# wiz16b8m4ct3_0_WIZ16B8M4CT3 register map
Vendor: Texas Instruments
Registers are 32-bit, read-write, reset 0x0 unless marked. A register's access mark holds for its fields unless they carry their own. Offsets are as the file gives them; [hi:lo] are bit positions; {n}, {i} and the like mark numbered series.

## wiz16b8m4ct3_0_WIZ16B8M4CT3 (part 8 of 12)
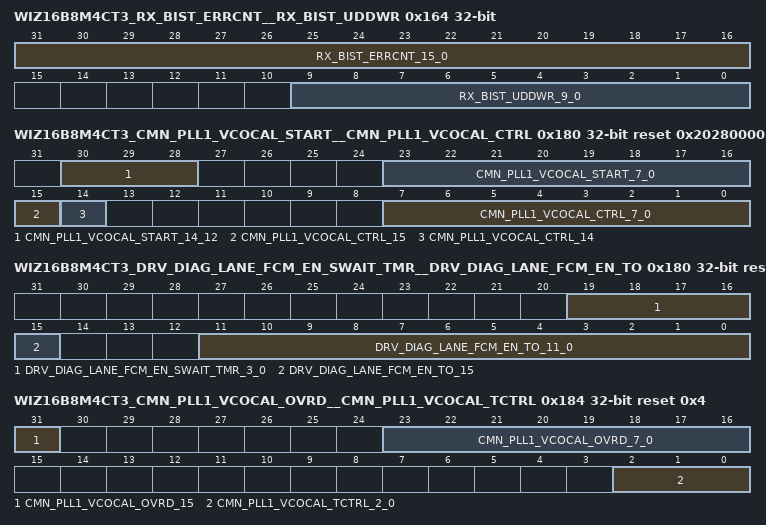
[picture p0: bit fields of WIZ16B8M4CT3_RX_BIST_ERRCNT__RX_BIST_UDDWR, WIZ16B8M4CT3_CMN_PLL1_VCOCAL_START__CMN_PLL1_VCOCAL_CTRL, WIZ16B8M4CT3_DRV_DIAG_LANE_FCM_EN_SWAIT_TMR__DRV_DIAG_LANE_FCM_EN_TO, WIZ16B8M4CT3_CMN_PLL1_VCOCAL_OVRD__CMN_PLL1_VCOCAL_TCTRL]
0x164 WIZ16B8M4CT3_RX_BIST_ERRCNT__RX_BIST_UDDWR access per field
  [31:16] RX_BIST_ERRCNT_15_0 ro — Receiver BIST error count: Indicates the number of BIST errors that have been observed by the receive BIST logic, since the last time the BIST error indicator logic was reset or restarted. This counter increments up to a maximum value of 16'hFFFF. Note : Due to the nature of the BIST PRBS error detection logic, when a bit error occurs in PRBS mode, two or three errors will be counted.
  [9:0] RX_BIST_UDDWR_9_0 wo — Receiver BIST user defined data: Writing a data word to this field will result in that data word being placed in the next available position in the receiver BIST user defined data FIFO. Note, when in 20 bit mode, all 10 of these bits are used. When in 16 bit mode, only the least significant 8 bits are used. Note: The FIFO in this implementation is 18 words deep. It is up to the user to not write more than 18 words of data into this FIFO. Exceeding this amount of data will generate unpredictable results.
0x180 WIZ16B8M4CT3_CMN_PLL1_VCOCAL_START__CMN_PLL1_VCOCAL_CTRL access per field reset 0x20280000
  [30:28] CMN_PLL1_VCOCAL_START_14_12 rw — VCO calibration initial step size control: This field specifies the initial step size for the VCO calibration state machine. The following are the values that can be used in this field, and the corresponding step sizes. 3'b000 : 1 3'b001 : 2 3'b010 : 4 3'b011 : 8 3'b100 : 16 3'b101 - 3'b111 : Reserved Note: This field is intended to be for diagnostics purposes only.
  [23:16] CMN_PLL1_VCOCAL_START_7_0 rw — VCO calibration code starting point value: This field specifies the starting VCO code that is used by the VCO calibration state machine. The purpose of this value is such that the VCO calibration process starts at a point that is, on average, relatively close to the final calibration point. This allows the calibration time to be reduced, on average. The encoding of this field is the same as what is described in the VCO calibration control register. Note: This field is intended to be for diagnostics purposes only. Note : This field must be set to a value that is always at least one step size away from the minimum and maximum calibration codes, and is a function of the step size specified in this register. For example, if the initial step size is 4, this value must be at least 4 greater than the minimum calibration code or 4 less than the maximum calibration code.
  [15] CMN_PLL1_VCOCAL_CTRL_15 rw — Start VCO calibration: Activating (1'b1) this bit will start a VCO calibration process. This bit must remain active until the VCO calibration process is complete (as indicated by the VCO calibration process done bit in this register). To start another VCO calibration process, the VCO calibration process done bit must have gone inactive from any prior calibration process. Note: This bit is intended to be for diagnostics purposes only. This calibration process is automatically activated internally by the PLL control state machine. When using this bit, the user must wait until after the internally activated process completes.
  [14] CMN_PLL1_VCOCAL_CTRL_14 ro — VCO calibration process done: This bit will be set to 1'b1 when the VCO calibration process is complete. It will be cleared by the deactivation of the Start VCO calibration bit in this register. Note: This bit is intended to be for diagnostics purposes only. Note: This bit is not likely to be observed as being set after internal automatic calibration is complete, because the internally generated run signal will be driven inactive immediately after the done signal is activated, and therefore the internal done signal will be cleared.
  [7:0] CMN_PLL1_VCOCAL_CTRL_7_0 ro — VCO calibration code: This is the calibration code that was determined by the VCO calibration process. This signal is valid when the VCO calibration process is complete. The values of this field correspond to different frequency bands the VCO will operate in. The frequency bands are controlled by the number of capacitors that are switched in the VCO analog circuit. This field specifies the number of capacitors that are switched in. The following are the values for this code: 8'b00000000: 0 Capacitors activated 8'b00000001: 1 Capacitor activated 8'b00000010: 2 Capacitors activated 8'b00000011: 3 Capacitors activated ... 8'b11111110: 254 Capacitors activated 8'b11111111: 255 Capacitors activated Note: This register is intended to be for diagnostics purposes only. Note: The reset value for this field is with the PLL controller power island switched off. In cases where this power island is switched on, the reset value be 8'h28.
0x180 WIZ16B8M4CT3_DRV_DIAG_LANE_FCM_EN_SWAIT_TMR__DRV_DIAG_LANE_FCM_EN_TO reset 0x601F4
  [19:16] DRV_DIAG_LANE_FCM_EN_SWAIT_TMR_3_0 — Lane fast common mode enable sample wait timer value: This specifies the number of reference clock cycles the fast establishment of common mode process will wait between changing the state of the signals controlling the analog common mode sense circuits, and testing the results of the new state.
  [15] DRV_DIAG_LANE_FCM_EN_TO_15 — Bypass fast establishment of common mode enable: When enabled, the fast establishment of common mode function will be bypassed. When bypassed, the lane fast common mode enable timeout value field in this register can be used to implement a programmable delay between when fast establishment of common mode is normally initiated, and when it will complete.
  [11:0] DRV_DIAG_LANE_FCM_EN_TO_11_0 — Lane fast common mode enable timeout value: The usage of the value of this field is a function of the state of the bypass fast establishment of common mode enable bit in this register. Bypass disabled (normal operation): This specifies the maximum number of reference clock cycles the fast establishment of common mode process will wait for the tx_{p,m} signals to be reported as above the reference voltage, before timing out. The default value of this register corresponds to a delay of 20 uSec. Bypass enabled: This can be used to specify the number of reference clock cycles between when fast establishment of common mode would normally be initiated, and when it is acknowledged to have been completed.
0x184 WIZ16B8M4CT3_CMN_PLL1_VCOCAL_OVRD__CMN_PLL1_VCOCAL_TCTRL reset 0x4
  [31] CMN_PLL1_VCOCAL_OVRD_15 — VCO calibration code override enable: Activating (1'b1) this bit allows the VCO code determined during the automatic VCO calibration process to be overridden by the value driven by the VCO calibration code override value field in this register. Note: This bit is intended to be for diagnostics purposes only. Note: This bit should not be activated while a calibration is currently in progress.
  [23:16] CMN_PLL1_VCOCAL_OVRD_7_0 — VCO calibration code override value: This field is used to override the VCO code determined during the automatic VCO calibration process. The VCO code driven on this field is valid when the VCO calibration code override enable bit in this register is active. The encoding of this field is the same as what is described in the VCO calibration control register. Note: This field is intended to be for diagnostics purposes only.
  [2:0] CMN_PLL1_VCOCAL_TCTRL_2_0 — VCO calibration initial time scale control: This field specifies the calibration start time scaling factor applied to the VCO calibration when running the initial step size for the calibration code if not set to 1. Setting this value to a value other than 1 will reduce the calibration measurement time by the amount specified below. Then when the final calibration steps are made the full calibration time will be used to get the appropriate amount of resolution. 3'b000 : Div 1 3'b001 : Div 2 3'b010 : Div 4 3'b011 : Div 8 3'b100 : Div 16 3'b101 : Div 32 3'b110 : Div 64 3'b111 : Div 128
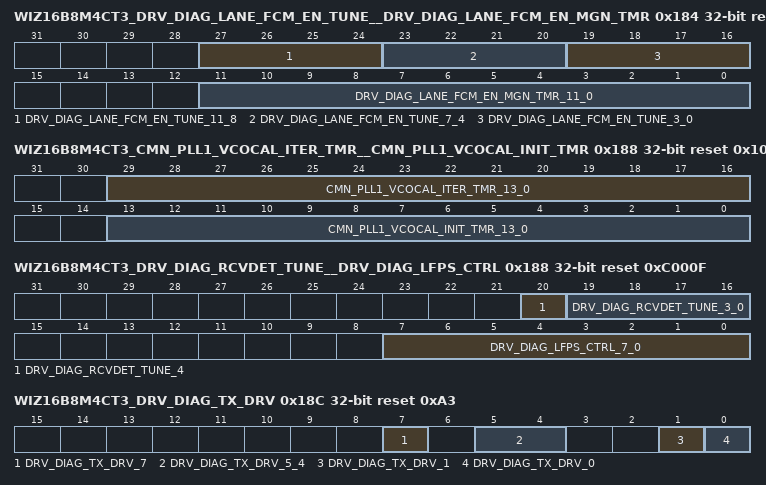
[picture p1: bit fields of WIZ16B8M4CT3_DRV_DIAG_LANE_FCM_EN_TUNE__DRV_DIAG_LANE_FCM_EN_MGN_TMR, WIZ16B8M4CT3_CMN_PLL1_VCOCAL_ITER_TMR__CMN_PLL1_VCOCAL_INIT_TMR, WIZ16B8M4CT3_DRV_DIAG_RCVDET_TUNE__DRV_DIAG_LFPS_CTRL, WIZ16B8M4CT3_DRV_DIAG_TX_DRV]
0x184 WIZ16B8M4CT3_DRV_DIAG_LANE_FCM_EN_TUNE__DRV_DIAG_LANE_FCM_EN_MGN_TMR reset 0x8C40096
  [27:24] DRV_DIAG_LANE_FCM_EN_TUNE_11_8 — Common mode sense reference DAC voltage initial test: This field sets the common mode detect reference voltage for the common mode detect comparator, when the fast establishment of common mode function is checking the initial state of the txda_cm_sense_comp_out signal. This field drives the txda_cm_sense_vref_dac signal going to the analog, and it is only driven when the fast establishment of common mode function is enabled. 4'b0000 : Minimum ... 4'b1111 : Maximum
  [23:20] DRV_DIAG_LANE_FCM_EN_TUNE_7_4 — Common mode sense reference DAC voltage high test: This field sets the common mode detect reference voltage for the common mode detect comparator, when the fast establishment of common mode function is waiting for the txda_cm_sense_comp_out signal from the analog to be driven high. This field drives the txda_cm_sense_vref_dac signal going to the analog, and it is only driven when the fast establishment of common mode function is enabled. 4'b0000 : Minimum ... 4'b1111 : Maximum
  [19:16] DRV_DIAG_LANE_FCM_EN_TUNE_3_0 — Common mode sense reference DAC voltage low test: This field sets the common mode detect reference voltage for the common mode detect comparator, when the fast establishment of common mode function is waiting for the txda_cm_sense_comp_out signal from the analog to be driven low. This field drives the txda_cm_sense_vref_dac signal going to the analog, and it is only driven when the fast establishment of common mode function is enabled. 4'b0000 : Minimum ... 4'b1111 : Maximum
  [11:0] DRV_DIAG_LANE_FCM_EN_MGN_TMR_11_0 — Lane fast common mode enable margin timer value: This specifies the number of reference clock cycles the fast establishment of common mode process will enable all the margin segments for. The default value of this register corresponds to a delay of 6 uSec.
0x188 WIZ16B8M4CT3_CMN_PLL1_VCOCAL_ITER_TMR__CMN_PLL1_VCOCAL_INIT_TMR reset 0x1003E8
  [29:16] CMN_PLL1_VCOCAL_ITER_TMR_13_0 — Iteration wait timer value: This is the number of clocks to wait between when a calibration code is driven to the analog, and when the clock rates are measured.
  [13:0] CMN_PLL1_VCOCAL_INIT_TMR_13_0 — Initialization wait timer value: This is the number of clocks to wait between when the analog VCO calibration circuits are enabled, and when the first calibration code is driven to the analog. Note: The reset value for this field corresponds to a time of 10 uSec.
0x188 WIZ16B8M4CT3_DRV_DIAG_RCVDET_TUNE__DRV_DIAG_LFPS_CTRL reset 0xC000F
  [20] DRV_DIAG_RCVDET_TUNE_4 — Receiver detect comparators output and or control: This bit controls how the receiver detect comparators are used to drive the txda_rcvdet_detected_n signal to the digital. This bit drives the txda_rcvdet_and_orb signal going to the analog. 1'b0: Comparator outputs are ORed to drive txda_rcvdet_detected_n. 1'b1: Comparator outputs are ANDed to drive txda_rcvdet_detected_n.
  [19:16] DRV_DIAG_RCVDET_TUNE_3_0 — Receiver detect reference DAC voltage: This field sets the receiver detect reference voltage for the receiver detect comparator. This field drives the txda_rcvdet_vref_dac signal going to the analog. 4'b0000 : Minimum ... 4'b1111 : Maximum
  [7:0] DRV_DIAG_LFPS_CTRL_7_0 — LFPS half period clocks: Specifies the number of clock cycles required to implement one half of a LFPS period, by the transmitter LFPS controller.
0x18C WIZ16B8M4CT3_CMN_PLL1_VCOCAL_REFTIM_START reset 0xC5F
  [13:0] CMN_PLL1_VCOCAL_REFTIM_START_13_0 — PLL VCO calibration reference clock timer start value : This is the value that is loaded into the reference clock timer as the starting point for that timer, when running VCO calibration. The value in this field must correspond to a time that is approximately one full spread spectrum cycle long (31.67 uSec) Note: The actual number of clocks counted is one larger than what is specified by this field.
0x18C WIZ16B8M4CT3_DRV_DIAG_TX_DRV reset 0xA3
  [7] DRV_DIAG_TX_DRV_7 — TX boost enable: Increases the transmitter amplitude for fast data transitions, by controlling the txda_drv_boost_en signal going to the analog.
  [5:4] DRV_DIAG_TX_DRV_5_4 — TX boost tune: Controls the transmitter boost amplitude when the transmitter boost function is enabled using the TX boost enable bit in this register, by controlling the txda_drv_boost_tune signal going to the analog. The following specifies the encoding of this field. 2'b00: Minimum Boost 2'b01: 2'b10: 2'b11: Maximum Boost
  [1] DRV_DIAG_TX_DRV_1 — TX pre-driver pull up control: When the pre-driver is disabled, this bit controls the state of the pre-driver output, by controlling the txda_drv_predrv_pullup signal going to the analog. 1'b0 : Pulled low 1'b1 : Pulled high
  [0] DRV_DIAG_TX_DRV_0 — TX driver margin type: Selects the margining type the driver will operate in, by controlling the txda_drv_margin_type signal going to the analog. 1'b0 : Classical margining - High power margining that complies with the driver differential and common-mode output impedance specs. 1'b1 : Low-Power margining - Low power margining that complies with the driver differential output impedance spec. However, this violates the driver common-mode output impedance spec to save power whenever a reduced swing driver configuration is used. Note: When fast establishment of common mode is active, the analog signal that this drives will be forced to 1'b0.
0x190 WIZ16B8M4CT3_CMN_PLL1_VCOCAL_PLLCNT_START reset 0xC5F
  [13:0] CMN_PLL1_VCOCAL_PLLCNT_START_13_0 — PLL VCO calibration PLL clock counter start value : This is the value that is loaded into the PLL clock counter as the starting point for that counter, when running VCO calibration. When programming this register, it is important to understand how the frequency of the cmnda_pll0_fb_divider_clk is calculated relative to the reference clock. This is described in section 10.4 Dual VCO PLL on page 411. Note: The actual number of clocks counted is one larger than what is specified by this field.
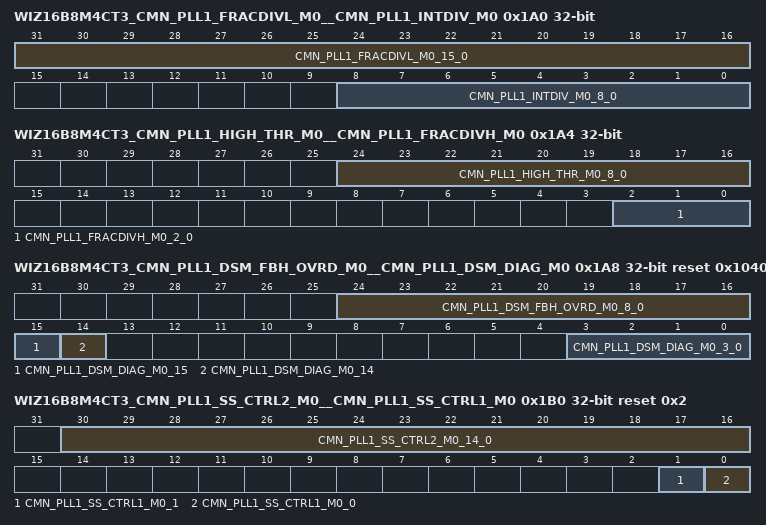
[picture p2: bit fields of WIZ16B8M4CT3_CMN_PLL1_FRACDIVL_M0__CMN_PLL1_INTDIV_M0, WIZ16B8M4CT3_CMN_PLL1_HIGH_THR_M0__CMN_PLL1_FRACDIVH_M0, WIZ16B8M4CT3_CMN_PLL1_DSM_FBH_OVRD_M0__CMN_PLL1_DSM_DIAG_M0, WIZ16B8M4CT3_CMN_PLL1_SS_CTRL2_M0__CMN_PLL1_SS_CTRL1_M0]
0x1A0 WIZ16B8M4CT3_CMN_PLL1_FRACDIVL_M0__CMN_PLL1_INTDIV_M0
  [31:16] CMN_PLL1_FRACDIVL_M0_15_0 — pll_fb_div_fractional: Value of the pll_fb_div_fractional[15:0] signal.
  [8:0] CMN_PLL1_INTDIV_M0_8_0 — pll_fb_div_integer value: Value of the pll_fb_div_integer signal.
0x1A4 WIZ16B8M4CT3_CMN_PLL1_HIGH_THR_M0__CMN_PLL1_FRACDIVH_M0
  [24:16] CMN_PLL1_HIGH_THR_M0_8_0 — pll_fb_div_high_theshold: Value of the pll_fb_div_high_threshold signal. The value of this register should be 2/3 the value of the combined integer and fractional divider values, and rounded up to the next even number.
  [2:0] CMN_PLL1_FRACDIVH_M0_2_0 — pll_fb_div_fractional: Value of the pll_fb_div_fractional[18:16] signal.
0x1A8 WIZ16B8M4CT3_CMN_PLL1_DSM_FBH_OVRD_M0__CMN_PLL1_DSM_DIAG_M0 reset 0x104004
  [24:16] CMN_PLL1_DSM_FBH_OVRD_M0_8_0 — PLL feedback divider high override value : When enabled by the PLL feedback divider override enable bit in the PLL 1 delta sigma modulator diagnostics register mode 0 on page 126, the value in this field will be used to override the value on the cmnda_pll1_fb_div_high signal. Note: The value of this register should be 2/3 the value of the combined PLL feedback divider high and low values, and rounded up to the next even number.
  [15] CMN_PLL1_DSM_DIAG_M0_15 — Delta sigma bypass enable: When set to 1'b1, the delta sigma modulator will be bypassed, and the output will be the value specified for the internal pll_fb_div_integer signal.
  [14] CMN_PLL1_DSM_DIAG_M0_14 — PLL feedback divider override enable : When active (1'b1), the feedback divider low and high override values in the PLL 1 delta sigma modulator feedback divider value high override register mode 0 on page 126 and PLL 1 delta sigma modulator feedback divider value low override register mode 0 on page 126 registers will be used to override the feedback divider values driven to the analog.
  [3:0] CMN_PLL1_DSM_DIAG_M0_3_0 — PLL feedback divider latency adjustment: This signal specifies a value to be subtracted from the feedback divider settings before they are output on the cmnda_pll1_fb_div_high and cmnda_pll1_fb_div_low signals.
0x1AC WIZ16B8M4CT3_CMN_PLL1_DSM_FBL_OVRD_M0 reset 0x10
  [8:0] CMN_PLL1_DSM_FBL_OVRD_M0_8_0 — PLL feedback divider low override value : When enabled by the PLL feedback divider override enable bit in the PLL 1 delta sigma modulator diagnostics register mode 0 on page 126, the value in this field will be used to override the value on the cmnda_pll1_fb_div_low signal.
0x1B0 WIZ16B8M4CT3_CMN_PLL1_SS_CTRL2_M0__CMN_PLL1_SS_CTRL1_M0 reset 0x2
  [30:16] CMN_PLL1_SS_CTRL2_M0_14_0 — Amplitude step size: Value of the amplitude_step_size pin on the spread spectrum waveform generator. Note: This field should not be set to 0 when spread spectrum is enabled.
  [1] CMN_PLL1_SS_CTRL1_M0_1 — Spread spectrum waveform generator disable: Setting this bit to a 1'b1 will disable the spread spectrum waveform generator.
  [0] CMN_PLL1_SS_CTRL1_M0_0 — Spread spectrum enable during VCO calibration : Setting this bit to a 1'b1 will enable the spread spectrum function while VCO calibration is taking place.
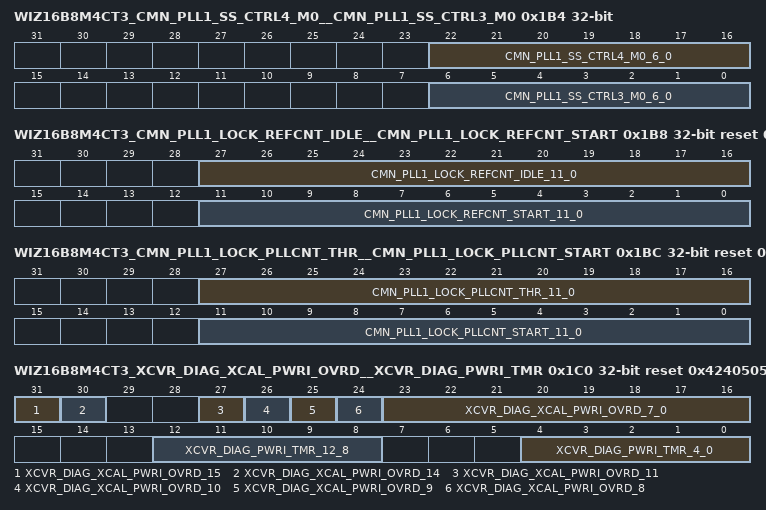
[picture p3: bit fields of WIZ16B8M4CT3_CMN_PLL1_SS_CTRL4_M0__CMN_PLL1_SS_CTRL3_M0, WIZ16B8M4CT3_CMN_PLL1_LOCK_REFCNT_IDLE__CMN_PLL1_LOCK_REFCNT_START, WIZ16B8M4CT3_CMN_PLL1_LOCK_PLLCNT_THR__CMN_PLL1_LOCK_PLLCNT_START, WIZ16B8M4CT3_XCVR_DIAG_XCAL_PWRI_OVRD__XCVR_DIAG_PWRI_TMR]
0x1B4 WIZ16B8M4CT3_CMN_PLL1_SS_CTRL4_M0__CMN_PLL1_SS_CTRL3_M0
  [22:16] CMN_PLL1_SS_CTRL4_M0_6_0 — Time step size: Value for the time_step_size pin on the spread spectrum waveform generator. Note: This field should not be set to 0 when spread spectrum is enabled.
  [6:0] CMN_PLL1_SS_CTRL3_M0_6_0 — Number of steps: Value of the num_steps pin on the spread spectrum waveform generator. Note: This field should not be set to 0 when spread spectrum is enabled.
0x1B8 WIZ16B8M4CT3_CMN_PLL1_LOCK_REFCNT_IDLE__CMN_PLL1_LOCK_REFCNT_START reset 0x400C8
  [27:16] CMN_PLL1_LOCK_REFCNT_IDLE_11_0 — PLL lock reference counter idle value : This is the value used by the PLL lock detection logic to specify the number of reference clocks between each phase of counting PLL clocks.
  [11:0] CMN_PLL1_LOCK_REFCNT_START_11_0 — PLL lock reference counter start value : This is the value that is loaded into the PLL lock detect reference counter as the starting point for that counter, when checking for PLL lock. Note: The value required here is a function of the PLL feedback divider clock mode and the reference clock frequency. Overview information in regards to this can be found in section 4.2 Reference Clock Related Clocking and Reset on page 288 and section 4.9 Reference Clock Related Clock Rate Summary on page 319. The following bullet points specify the required time the value in this register is required to generate. By default, the value in this register is set for FBR mode with a 100 MHz reference clock. FBR mode and reference clock frequency greater than or equal to 100 MHz: 2 uSec FBR mode and reference clock frequency less than 100 MHz: 8 uSec DR mode: 800 nSec
0x1BC WIZ16B8M4CT3_CMN_PLL1_LOCK_PLLCNT_THR__CMN_PLL1_LOCK_PLLCNT_START reset 0x300C8
  [27:16] CMN_PLL1_LOCK_PLLCNT_THR_11_0 — PLL lock counter threshold value : This is the value used by the PLL lock detection logic to determine if the PLL has locked. If the two counters in the PLL lock detection logic differ by less than this value, the PLL is considered locked.
  [11:0] CMN_PLL1_LOCK_PLLCNT_START_11_0 — PLL lock PLL counter start value : This is the value that is loaded into the PLL lock detect PLL counter as the starting point for that counter, when checking for PLL lock. The value is the number of PLL feedback divider clock edges that are expected during the time specified by the PLL 0 lock reference counter start value register on page 115. When programming this register, it is important to understand how the frequency of the cmnda_pll0_fb_divider_clk is calculated relative to the reference clock. This is described in section 10.4 Dual VCO PLL on page 411.
0x1C0 WIZ16B8M4CT3_XCVR_DIAG_XCAL_PWRI_OVRD__XCVR_DIAG_PWRI_TMR access per field reset 0x4240505
  [31] XCVR_DIAG_XCAL_PWRI_OVRD_15 rw — Power island controller input override enable: When enabled, the power island control state machine input override bits in this register will drive the power island control state machine directly, and override any control from other state machines in the macro. Note: The CDB power island must be triggered to be enabled, by accessing a register outside of the common control module control and diagnostic registers space, prior to enabling this function. Note: This bit must never change state in the same register write that any of the override bits it controls in this register are changed. Note: The value of this field must be the same for all lanes that make up a link. 1'b0: Override disabled 1'b1: Override enabled
  [30] XCVR_DIAG_XCAL_PWRI_OVRD_14 rw — Power island controller output override enable: When enabled, the power island control state machine output override bits in this register will drive the power island control state machine outputs, and override any control from power island control state machine. Note: This bit must never change state in the same register write that any of the override bits it controls in this register are changed. Note: The value of this field must be the same for all lanes that make up a link. 1'b0: Override disabled 1'b1: Override enabled
  [27] XCVR_DIAG_XCAL_PWRI_OVRD_11 rw — Power suspend request override: When enabled, this bit will override the power_suspend_req input of the power island control state machine. Note: The value of this field must be the same for all lanes that make up a link.
  [26] XCVR_DIAG_XCAL_PWRI_OVRD_10 ro — Power suspend acknowledge: This is the current state of the power_suspend_ack output from the power island control state machine. Note: This bit will always be set to 1'b1 after the power island is enabled, as a function of the power island controller input override enable bit in this register.
  [25] XCVR_DIAG_XCAL_PWRI_OVRD_9 rw — Power recover request override: When enabled, this bit will override the power_recover_req input of the power island control state machine. Note: The value of this field must be the same for all lanes that make up a link.
  [24] XCVR_DIAG_XCAL_PWRI_OVRD_8 ro — Power recover acknowledge: This is the current state of the power_recover_ack output from the power island control state machine. Note: This bit will always be set to 1'b1 after the power island is enabled, as a function of the power island controller input override enable bit in this register.
  [23:16] XCVR_DIAG_XCAL_PWRI_OVRD_7_0 rw — Power island controller output override: When enabled, the bits in this field will override the output signals from the power island control state machine. The following are the power island control state machine output signals, and the bits in this field that they are associated with. Bit 7: state_sandh Bit 6: state_ret_save Bit 5: state_ret_restore (active low) Bit 4: power_en_ph_1 Bit 3: power_en_ph_2 Bit 2: power_isolation Bit 1: power_por_reset_n Bit 0: power_rstr_reset_n The default value of the bits in this register are such that the power island is not forced to be switched on when the power island controller output override enable bit in this register is enabled. When using this register to switch this power island on and off, the bits in this field are required to change in a specific order with individual register writes. The writes must happen in the order specified below. 8'b00100100 : Power island is not being forced on 8'b10100100 8'b10110100 8'b10111100 8'b10111111 8'b10111011 8'b00111011 : Power island is being forced on 8'b10111011 8'b10111111 8'b11111111 8'b10111111 8'b10111110 8'b10100110 : Power island is being forced off, and in state retention 8'b10110110 8'b10111110 8'b10111111 8'b10011111 8'b10111111 8'b10111011 8'b00111011 : Power island is being forced on, with state restored Note: The value of this field must be the same for all lanes that make up a link.
  [12:8] XCVR_DIAG_PWRI_TMR_12_8 rw — Power enable phase 2 timer value: This specifies the number of PSM clock cycles the power island control state machines in the transceiver will wait in the power phase 2 enable states, in order to allow enough time for the second phase of the switched domain to power up, before deactivating the isolation functions. The default value of this register corresponds to a delay of 40 nSec. Note: A value of 0 in this field is not valid, and will result in a delay of 1 clock cycle. Note: The value of this field must be the same for all lanes that make up a link.
  [4:0] XCVR_DIAG_PWRI_TMR_4_0 rw — Power enable phase 1 timer value: This specifies the number of PSM clock cycles the power island control state machines in the transceiver will wait in the power phase 1 enable states, in order to allow enough time for the first phase of the switched domain to power up, before enabling the second phase of the power up. The default value of this register corresponds to a delay of 40 nSec. Note: A value of 0 in this field is not valid, and will result in a delay of 1 clock cycle. Note: The value of this field must be the same for all lanes that make up a link.
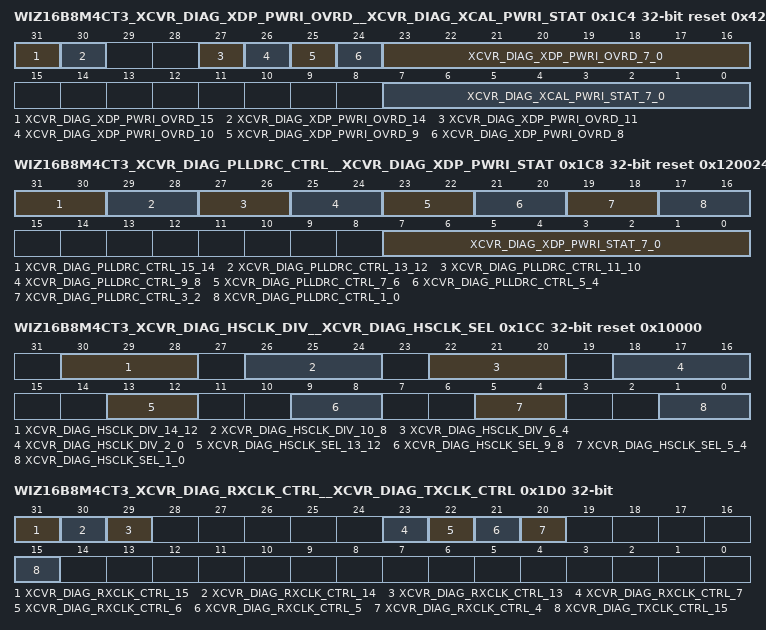
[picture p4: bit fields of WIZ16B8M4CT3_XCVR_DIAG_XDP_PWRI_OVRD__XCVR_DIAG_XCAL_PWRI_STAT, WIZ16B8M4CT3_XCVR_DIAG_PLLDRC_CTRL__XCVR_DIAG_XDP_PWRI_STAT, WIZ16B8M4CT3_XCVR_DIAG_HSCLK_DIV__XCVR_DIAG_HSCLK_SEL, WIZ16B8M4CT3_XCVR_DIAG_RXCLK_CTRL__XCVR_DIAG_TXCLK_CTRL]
0x1C4 WIZ16B8M4CT3_XCVR_DIAG_XDP_PWRI_OVRD__XCVR_DIAG_XCAL_PWRI_STAT access per field reset 0x4240024
  [31] XCVR_DIAG_XDP_PWRI_OVRD_15 rw — Power island controller input override enable: When enabled, the power island control state machine input override bits in this register will drive the power island control state machine directly, and override any control from other state machines in the macro. Note: The CDB power island must be triggered to be enabled, by accessing a register outside of the common control module control and diagnostic registers space, prior to enabling this function. Note: This bit must never change state in the same register write that any of the override bits it controls in this register are changed. Note: The value of this field must be the same for all lanes that make up a link. 1'b0: Override disabled 1'b1: Override enabled
  [30] XCVR_DIAG_XDP_PWRI_OVRD_14 rw — Power island controller output override enable: When enabled, the power island control state machine output override bits in this register will drive the power island control state machine outputs, and override any control from power island control state machine. Note: This bit must never change state in the same register write that any of the override bits it controls in this register are changed. Note: The value of this field must be the same for all lanes that make up a link. 1'b0: Override disabled 1'b1: Override enabled
  [27] XCVR_DIAG_XDP_PWRI_OVRD_11 rw — Power suspend request override: When enabled, this bit will override the power_suspend_req input of the power island control state machine. Note: The value of this field must be the same for all lanes that make up a link.
  [26] XCVR_DIAG_XDP_PWRI_OVRD_10 ro — Power suspend acknowledge: This is the current state of the power_suspend_ack output from the power island control state machine. Note: This bit will always be set to 1'b1 after the power island is enabled, as a function of the power island controller input override enable bit in this register.
  [25] XCVR_DIAG_XDP_PWRI_OVRD_9 rw — Power recover request override: When enabled, this bit will override the power_recover_req input of the power island control state machine. Note: The value of this field must be the same for all lanes that make up a link.
  [24] XCVR_DIAG_XDP_PWRI_OVRD_8 ro — Power recover acknowledge: This is the current state of the power_recover_ack output from the power island control state machine. Note: This bit will always be set to 1'b1 when the power island controller input override enable bit in this register.
  [23:16] XCVR_DIAG_XDP_PWRI_OVRD_7_0 rw — Power island controller output override: When enabled, the bits in this field will override the output signals from the power island control state machine. The following are the power island control state machine output signals, and the bits in this field that they are associated with. Bit 7: state_sandh Bit 6: state_ret_save Bit 5: state_ret_restore (active low) Bit 4: power_en_ph_1 Bit 3: power_en_ph_2 Bit 2: power_isolation Bit 1: power_por_reset_n Bit 0: power_rstr_reset_n The default value of the bits in this register are such that the power island is not forced to be switched on when the power island controller output override enable bit in this register is enabled. When using this register to switch this power island on and off, the bits in this field are required to change in a specific order with individual register writes. The writes must happen in the order specified below. 8'b00100100 : Power island is not being forced on 8'b10100100 8'b10110100 8'b10111100 8'b10111111 8'b10111011 8'b00111011 : Power island is being forced on 8'b10111011 8'b10111111 8'b11111111 8'b10111111 8'b10111110 8'b10100110 : Power island is being forced off, and in state retention 8'b10110110 8'b10111110 8'b10111111 8'b10011111 8'b10111111 8'b10111011 8'b00111011 : Power island is being forced on, with state restored Note: The value of this field must be the same for all lanes that make up a link.
  [7:0] XCVR_DIAG_XCAL_PWRI_STAT_7_0 ro — Power island controller output status: This field indicates the current state of the output signals from the power island control state machine. The following are the power island control state machine output signals, and the bits in this field that they are associated with. Bit 7: state_sandh Bit 6: state_ret_save Bit 5: state_ret_restore (active low) Bit 4: power_en_ph_1 Bit 3: power_en_ph_2 Bit 2: power_isolation Bit 1: power_por_reset_n Bit 0: power_rstr_reset_n
0x1C8 WIZ16B8M4CT3_XCVR_DIAG_PLLDRC_CTRL__XCVR_DIAG_XDP_PWRI_STAT access per field reset 0x120024
  [31:30] XCVR_DIAG_PLLDRC_CTRL_15_14 rw — Digital PLL clock select standard mode 3: This bit controls which full rate PLL clock is selected, when xcvr_standard_mode is set to 2'b11. 2'b00 : PLL clock 0 from the PLL 0. 2'b01 : PLL clock 1 from the PLL 0. 2'b10 : PLL clock 0 from the PLL 1. 2'b11 : PLL clock 1 from the PLL 1.
  [29:28] XCVR_DIAG_PLLDRC_CTRL_13_12 rw — Digital PLL data rate divider standard mode 3 value: This field will directly control the xcvr_pll_clk_datart_div signal, which controls which divided clock is selected when generating the xcvr_pll_clk_datart clock, when xcvr_standard_mode is set to 2'b11. 2'b00 : Divide by 1. 2'b01 : Divide by 2. 2'b10 : Divide by 4. 2'b11 : Divide by 8.
  [27:26] XCVR_DIAG_PLLDRC_CTRL_11_10 rw — Digital PLL clock select standard mode 2: This bit controls which full rate PLL clock is selected, when xcvr_standard_mode is set to 2'b10. 2'b00 : PLL clock 0 from the PLL 0. 2'b01 : PLL clock 1 from the PLL 0. 2'b10 : PLL clock 0 from the PLL 1. 2'b11 : PLL clock 1 from the PLL 1.
  [25:24] XCVR_DIAG_PLLDRC_CTRL_9_8 rw — Digital PLL data rate divider standard mode 2 value: This field will directly control the xcvr_pll_clk_datart_div signal, which controls which divided clock is selected when generating the xcvr_pll_clk_datart clock, when xcvr_standard_mode is set to 2'b10. 2'b00 : Divide by 1. 2'b01 : Divide by 2. 2'b10 : Divide by 4. 2'b11 : Divide by 8.
  [23:22] XCVR_DIAG_PLLDRC_CTRL_7_6 rw — Digital PLL clock select standard mode 1: This bit controls which full rate PLL clock is selected, when xcvr_standard_mode is set to 2'b01. 2'b00 : PLL clock 0 from the PLL 0. 2'b01 : PLL clock 1 from the PLL 0. 2'b10 : PLL clock 0 from the PLL 1. 2'b11 : PLL clock 1 from the PLL 1.
  [21:20] XCVR_DIAG_PLLDRC_CTRL_5_4 rw — Digital PLL data rate divider standard mode 1 value: This field will directly control the xcvr_pll_clk_datart_div signal, which controls which divided clock is selected when generating the xcvr_pll_clk_datart clock, when xcvr_standard_mode is set to 2'b01. 2'b00 : Divide by 1. 2'b01 : Divide by 2. 2'b10 : Divide by 4. 2'b11 : Divide by 8.
  [19:18] XCVR_DIAG_PLLDRC_CTRL_3_2 rw — Digital PLL clock select standard mode 0: This bit controls which full rate PLL clock is selected, when xcvr_standard_mode is set to 2'b00. 2'b00 : PLL clock 0 from the PLL 0. 2'b01 : PLL clock 1 from the PLL 0. 2'b10 : PLL clock 0 from the PLL 1. 2'b11 : PLL clock 1 from the PLL 1.
  [17:16] XCVR_DIAG_PLLDRC_CTRL_1_0 rw — Digital PLL data rate divider standard mode 0 value: This field will directly control the xcvr_pll_clk_datart_div signal, which controls which divided clock is selected when generating the xcvr_pll_clk_datart clock, when xcvr_standard_mode is set to 2'b00. 2'b00 : Divide by 1. 2'b01 : Divide by 2. 2'b10 : Divide by 4. 2'b11 : Divide by 8.
  [7:0] XCVR_DIAG_XDP_PWRI_STAT_7_0 ro — Power island controller output status: This field indicates the current state of the output signals from the power island control state machine. The following are the power island control state machine output signals, and the bits in this field that they are associated with. Bit 7: state_sandh Bit 6: state_ret_save Bit 5: state_ret_restore (active low) Bit 4: power_en_ph_1 Bit 3: power_en_ph_2 Bit 2: power_isolation Bit 1: power_por_reset_n Bit 0: power_rstr_reset_n
0x1CC WIZ16B8M4CT3_XCVR_DIAG_HSCLK_DIV__XCVR_DIAG_HSCLK_SEL reset 0x10000
  [30:28] XCVR_DIAG_HSCLK_DIV_14_12 — Transceiver clock divider select standard mode 3: This field selects the divider value used to divide the selected analog high speed clock by when generating the transmit and receive clocks, when xcvr_standard_mode is set to 2'b11, by driving the xcvrda_xcvr_clk_div_sel signal to the analog, as specified below. 3'b000: Div 1 3'b001: Div 2 3'b010: Div 3 3'b011: Div 4 3'b100: Div 5 3'b101: Div 6 3'b110: Div 7 3'b111: Div 8
  [26:24] XCVR_DIAG_HSCLK_DIV_10_8 — Transceiver clock divider select standard mode 2: This field selects the divider value used to divide the selected analog high speed clock by when generating the transmit and receive clocks, when xcvr_standard_mode is set to 2'b10, by driving the xcvrda_xcvr_clk_div_sel signal to the analog, as specified below. 3'b000: Div 1 3'b001: Div 2 3'b010: Div 3 3'b011: Div 4 3'b100: Div 5 3'b101: Div 6 3'b110: Div 7 3'b111: Div 8
  [22:20] XCVR_DIAG_HSCLK_DIV_6_4 — Transceiver clock divider select standard mode 1: This field selects the divider value used to divide the selected analog high speed clock by when generating the transmit and receive clocks, when xcvr_standard_mode is set to 2'b01, by driving the xcvrda_xcvr_clk_div_sel signal to the analog, as specified below. 3'b000: Div 1 3'b001: Div 2 3'b010: Div 3 3'b011: Div 4 3'b100: Div 5 3'b101: Div 6 3'b110: Div 7 3'b111: Div 8
  [18:16] XCVR_DIAG_HSCLK_DIV_2_0 — Transceiver clock divider select standard mode 0: This field selects the divider value used to divide the selected analog high speed clock by when generating the transmit and receive clocks, when xcvr_standard_mode is set to 2'b00, by driving the xcvrda_xcvr_clk_div_sel signal to the analog, as specified below. 3'b000: Div 1 3'b001: Div 2 3'b010: Div 3 3'b011: Div 4 3'b100: Div 5 3'b101: Div 6 3'b110: Div 7 3'b111: Div 8
  [13:12] XCVR_DIAG_HSCLK_SEL_13_12 — High speed clock select standard mode 3: This specifies which analog high speed clock is selected when xcvr_standard_mode is set to 2'b11, by driving the xcvrda_clk_sel signal to the analog, as specified below. 2'b00 : clock 0. 2'b01 : clock 1. 2'b10 : Reserved. 2'b11 : Reserved.
  [9:8] XCVR_DIAG_HSCLK_SEL_9_8 — High speed clock select standard mode 2: This specifies which analog high speed clock is selected when xcvr_standard_mode is set to 2'b10, by driving the xcvrda_clk_sel signal to the analog, as specified below. 2'b00 : clock 0. 2'b01 : clock 1. 2'b10 : Reserved. 2'b11 : Reserved.
  [5:4] XCVR_DIAG_HSCLK_SEL_5_4 — High speed clock select standard mode 1: This specifies which analog high speed clock is selected when xcvr_standard_mode is set to 2'b01, by driving the xcvrda_clk_sel signal to the analog, as specified below. 2'b00 : clock 0. 2'b01 : clock 1. 2'b10 : Reserved. 2'b11 : Reserved.
  [1:0] XCVR_DIAG_HSCLK_SEL_1_0 — High speed clock select standard mode 0: This specifies which analog high speed clock is selected when xcvr_standard_mode is set to 2'b00, by driving the xcvrda_clk_sel signal to the analog, as specified below. 2'b00 : clock 0. 2'b01 : clock 1. 2'b10 : Reserved. 2'b11 : Reserved.
0x1D0 WIZ16B8M4CT3_XCVR_DIAG_RXCLK_CTRL__XCVR_DIAG_TXCLK_CTRL
  [31] XCVR_DIAG_RXCLK_CTRL_15 — RX deserializer clock invert: This bit is used to optionally invert the deserializer clock (rxda_des_clk) for diagnostic purposes.
  [30] XCVR_DIAG_RXCLK_CTRL_14 — RX 2x clock enable: This bit enables the receiver 2x clock function, by driving the rxda_des_clk_2x_en signal going to the analog. Note: This clock is only designed to be used in modes where the data width is 20 bits. 1'b0 : Disabled 1'b1 : Enabled
  [29] XCVR_DIAG_RXCLK_CTRL_13 — RX PI E path clock select: Controls which PI clock drives the E path clocks, by driving the rxda_pi_i_drv_e_en signal going to the analog. 1'b0: E PI clock 1'b1: IQ PI clock
  [23] XCVR_DIAG_RXCLK_CTRL_7 — PI output clock divider enable standard mode 3: This bit controls the rxda_pi_out_clk_div_en to enable the PI output clock divider, when xcvr_standard_mode is set to 2'b11. 1'b0 : Disabled 1'b1 : Enabled
  [22] XCVR_DIAG_RXCLK_CTRL_6 — PI output clock divider enable standard mode 2: This bit controls the rxda_pi_out_clk_div_en to enable the PI output clock divider, when xcvr_standard_mode is set to 2'b10. 1'b0 : Disabled 1'b1 : Enabled
  [21] XCVR_DIAG_RXCLK_CTRL_5 — PI output clock divider enable standard mode 1: This bit controls the rxda_pi_out_clk_div_en to enable the PI output clock divider, when xcvr_standard_mode is set to 2'b01. 1'b0 : Disabled 1'b1 : Enabled
  [20] XCVR_DIAG_RXCLK_CTRL_4 — PI output clock divider enable standard mode 0: This bit controls the rxda_pi_out_clk_div_en to enable the PI output clock divider, when xcvr_standard_mode is set to 2'b00. 1'b0 : Disabled 1'b1 : Enabled
  [15] XCVR_DIAG_TXCLK_CTRL_15 — TX serializer clock invert: This bit is used to optionally invert the serializer clock (txda_ser_clk) for diagnostic purposes.
